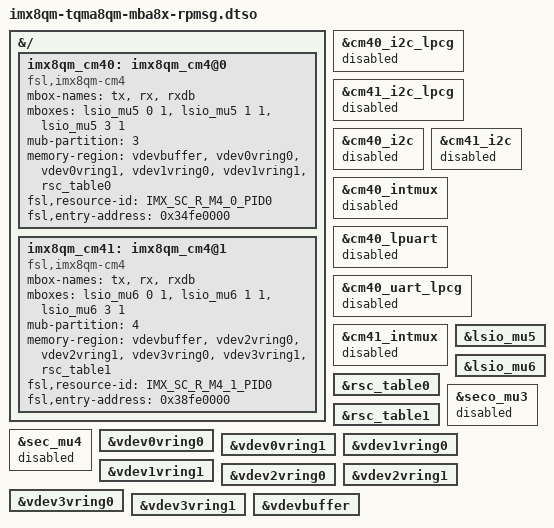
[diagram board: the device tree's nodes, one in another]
// SPDX-License-Identifier: (GPL-2.0-or-later OR MIT)
/*
 * Copyright (c) 2021-2024 TQ-Systems GmbH <linux@ew.tq-group.com>,
 * D-82229 Seefeld, Germany.
 * Author: Alexander Stein
 */

/dts-v1/;
/plugin/;

#include <dt-bindings/firmware/imx/rsrc.h>

&{/} {
	imx8qm_cm40: imx8qm_cm4@0 {
		compatible = "fsl,imx8qm-cm4";
		mbox-names = "tx", "rx", "rxdb";
		mboxes = <&lsio_mu5 0 1
			  &lsio_mu5 1 1
			  &lsio_mu5 3 1>;
		/*
		 * partition ID the M4 is running in,
		 * assigned via imx-mkimage when building bootstream
		 */
		mub-partition = <3>;
		memory-region = <&vdevbuffer>, <&vdev0vring0>, <&vdev0vring1>,
				<&vdev1vring0>, <&vdev1vring1>, <&rsc_table0>;
		fsl,resource-id = <IMX_SC_R_M4_0_PID0>;
		fsl,entry-address = <0x34fe0000>;
	};

	imx8qm_cm41: imx8qm_cm4@1 {
		compatible = "fsl,imx8qm-cm4";
		mbox-names = "tx", "rx", "rxdb";
		mboxes = <&lsio_mu6 0 1
			  &lsio_mu6 1 1
			  &lsio_mu6 3 1>;
		/*
		 * partition ID the M4 is running in,
		 * assigned via imx-mkimage when building bootstream
		 */
		mub-partition = <4>;
		memory-region = <&vdevbuffer>, <&vdev2vring0>, <&vdev2vring1>,
				<&vdev3vring0>, <&vdev3vring1>, <&rsc_table1>;
		fsl,resource-id = <IMX_SC_R_M4_1_PID0>;
		fsl,entry-address = <0x38fe0000>;
	};
};

&cm40_i2c_lpcg {
	status = "disabled";
};

&cm41_i2c_lpcg {
	status = "disabled";
};

&cm40_i2c {
	status = "disabled";
};

&cm41_i2c {
	status = "disabled";
};

&cm40_intmux {
	status = "disabled";
};

&cm40_lpuart {
	status = "disabled";
};

&cm40_uart_lpcg {
	status = "disabled";
};

&cm41_intmux {
	status = "disabled";
};

&lsio_mu5 {
	status = "okay";
};

&lsio_mu6 {
	status = "okay";
};

&rsc_table0 {
	status = "okay";
};

&rsc_table1 {
	status = "okay";
};

&seco_mu3 {
	status = "disabled";
};

&sec_mu4 {
	status = "disabled";
};

&vdev0vring0 {
	status = "okay";
};

&vdev0vring1 {
	status = "okay";
};

&vdev1vring0 {
	status = "okay";
};

&vdev1vring1 {
	status = "okay";
};

&vdev2vring0 {
	status = "okay";
};

&vdev2vring1 {
	status = "okay";
};

&vdev3vring0 {
	status = "okay";
};

&vdev3vring1 {
	status = "okay";
};

&vdevbuffer {
	status = "okay";
};
